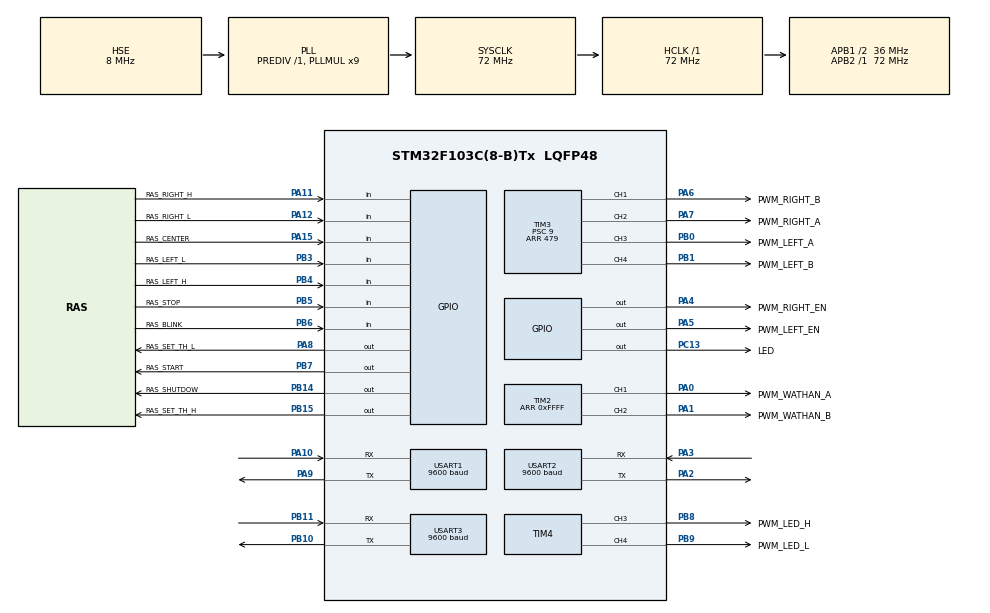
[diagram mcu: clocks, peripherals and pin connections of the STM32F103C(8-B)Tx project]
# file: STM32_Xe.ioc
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IWDG.Prescaler=IWDG_PRESCALER_64
Mcu.Family=STM32F1
Mcu.Name=STM32F103C(8-B)Tx
Mcu.Package=LQFP48
NVIC.PriorityGroup=NVIC_PRIORITYGROUP_4
NVIC.TIM1_UP_IRQn=true\:1\:0\:true\:false\:true\:true\:true
NVIC.USART1_IRQn=true\:0\:0\:false\:false\:true\:true\:true
NVIC.USART2_IRQn=true\:0\:0\:false\:false\:true\:true\:true
NVIC.USART3_IRQn=true\:0\:0\:false\:false\:true\:true\:true
PA0-WKUP.GPIO_Label=PWM_WATHAN_A
PA0-WKUP.Signal=S_TIM2_CH1_ETR
PA1.GPIO_Label=PWM_WATHAN_B
PA1.Signal=S_TIM2_CH2
PA10.GPIO_PuPd=GPIO_PULLUP
PA10.Mode=Asynchronous
PA10.Signal=USART1_RX
PA11.GPIO_Label=RAS_RIGHT_H
PA11.GPIO_PuPd=GPIO_PULLUP
PA11.Signal=GPIO_Input
PA12.GPIO_Label=RAS_RIGHT_L
PA12.GPIO_PuPd=GPIO_PULLUP
PA12.Signal=GPIO_Input
PA13.Mode=Serial_Wire
PA13.Signal=SYS_JTMS-SWDIO
PA14.Mode=Serial_Wire
PA14.Signal=SYS_JTCK-SWCLK
PA15.GPIO_Label=RAS_CENTER
PA15.GPIO_PuPd=GPIO_PULLUP
PA15.Signal=GPIO_Input
PA2.Mode=Asynchronous
PA2.Signal=USART2_TX
PA3.GPIO_PuPd=GPIO_PULLUP
PA3.Mode=Asynchronous
PA3.Signal=USART2_RX
PA4.GPIO_Label=PWM_RIGHT_EN
PA4.Signal=GPIO_Output
PA5.GPIO_Label=PWM_LEFT_EN
PA5.Signal=GPIO_Output
PA6.GPIO_Label=PWM_RIGHT_B
PA6.GPIO_Speed=GPIO_SPEED_FREQ_HIGH
PA6.Signal=S_TIM3_CH1
PA7.GPIO_Label=PWM_RIGHT_A
PA7.GPIO_Speed=GPIO_SPEED_FREQ_HIGH
PA7.Signal=S_TIM3_CH2
PA8.GPIO_Label=RAS_SET_TH_L
PA8.Signal=GPIO_Output
PA9.Mode=Asynchronous
PA9.Signal=USART1_TX
PB0.GPIO_Label=PWM_LEFT_A
PB0.GPIO_Speed=GPIO_SPEED_FREQ_HIGH
PB0.Signal=S_TIM3_CH3
PB1.GPIO_Label=PWM_LEFT_B
PB1.GPIO_Speed=GPIO_SPEED_FREQ_HIGH
PB1.Signal=S_TIM3_CH4
PB10.Mode=Asynchronous
PB10.Signal=USART3_TX
PB11.GPIO_PuPd=GPIO_PULLUP
PB11.Mode=Asynchronous
PB11.Signal=USART3_RX
PB14.GPIO_Label=RAS_SHUTDOW
PB14.Signal=GPIO_Output
PB15.GPIO_Label=RAS_SET_TH_H
PB15.Signal=GPIO_Output
PB3.GPIO_Label=RAS_LEFT_L
PB3.GPIO_PuPd=GPIO_PULLUP
PB3.Signal=GPIO_Input
PB4.GPIO_Label=RAS_LEFT_H
PB4.GPIO_PuPd=GPIO_PULLUP
PB4.Signal=GPIO_Input
PB5.GPIO_Label=RAS_STOP
PB5.GPIO_PuPd=GPIO_PULLUP
PB5.Signal=GPIO_Input
PB6.GPIO_Label=RAS_BLINK
PB6.GPIO_PuPd=GPIO_PULLUP
PB6.Signal=GPIO_Input
PB7.GPIO_Label=RAS_START
PB7.Signal=GPIO_Output
PB8.GPIO_Label=PWM_LED_H
PB8.Signal=S_TIM4_CH3
PB9.GPIO_Label=PWM_LED_L
PB9.Signal=S_TIM4_CH4
PC13-TAMPER-RTC.GPIO_Label=LED
PC13-TAMPER-RTC.GPIO_Speed=GPIO_SPEED_FREQ_HIGH
PC13-TAMPER-RTC.Signal=GPIO_Output
PD0-OSC_IN.Mode=HSE-External-Oscillator
PD0-OSC_IN.Signal=RCC_OSC_IN
PD1-OSC_OUT.Mode=HSE-External-Oscillator
PD1-OSC_OUT.Signal=RCC_OSC_OUT
ProjectManager.HeapSize=0x200
ProjectManager.StackSize=0x400
ProjectManager.TargetToolchain=MDK-ARM V5
RCC.AHBFreq_Value=72000000
RCC.APB1CLKDivider=RCC_HCLK_DIV2
RCC.APB1Freq_Value=36000000
RCC.APB1TimFreq_Value=72000000
RCC.APB2Freq_Value=72000000
RCC.APB2TimFreq_Value=72000000
RCC.HCLKFreq_Value=72000000
RCC.PLLMUL=RCC_PLL_MUL9
RCC.PLLSourceVirtual=RCC_PLLSOURCE_HSE
RCC.SYSCLKFreq_VALUE=72000000
RCC.SYSCLKSource=RCC_SYSCLKSOURCE_PLLCLK
RCC.USBFreq_Value=72000000
SH.S_TIM2_CH1_ETR.0=TIM2_CH1,PWM Generation1 CH1
SH.S_TIM2_CH2.0=TIM2_CH2,PWM Generation2 CH2
SH.S_TIM3_CH1.0=TIM3_CH1,PWM Generation1 CH1
SH.S_TIM3_CH2.0=TIM3_CH2,PWM Generation2 CH2
SH.S_TIM3_CH3.0=TIM3_CH3,PWM Generation3 CH3
SH.S_TIM3_CH4.0=TIM3_CH4,PWM Generation4 CH4
SH.S_TIM4_CH3.0=TIM4_CH3,PWM Generation3 CH3
SH.S_TIM4_CH4.0=TIM4_CH4,PWM Generation4 CH4
TIM1.AutoReloadPreload=TIM_AUTORELOAD_PRELOAD_ENABLE
TIM1.Period=59999
TIM1.Prescaler=11
TIM1.TIM_MasterOutputTrigger=TIM_TRGO_UPDATE
TIM2.AutoReloadPreload=TIM_AUTORELOAD_PRELOAD_DISABLE
TIM2.Channel-PWM\ Generation1\ CH1=TIM_CHANNEL_1
TIM2.Channel-PWM\ Generation2\ CH2=TIM_CHANNEL_2
TIM2.Period=0xFFFF
TIM3.Channel-PWM\ Generation1\ CH1=TIM_CHANNEL_1
TIM3.Channel-PWM\ Generation2\ CH2=TIM_CHANNEL_2
TIM3.Channel-PWM\ Generation3\ CH3=TIM_CHANNEL_3
TIM3.Channel-PWM\ Generation4\ CH4=TIM_CHANNEL_4
TIM3.Period=479
TIM3.Prescaler=9
TIM4.Channel-PWM\ Generation3\ CH3=TIM_CHANNEL_3
TIM4.Channel-PWM\ Generation4\ CH4=TIM_CHANNEL_4
USART1.BaudRate=9600
USART1.VirtualMode=VM_ASYNC
USART2.BaudRate=9600
USART2.VirtualMode=VM_ASYNC
USART3.BaudRate=9600
USART3.VirtualMode=VM_ASYNC
VP_IWDG_VS_IWDG.Mode=IWDG_Activate
VP_TIM1_VS_ClockSourceINT.Mode=Internal
VP_TIM2_VS_ClockSourceINT.Mode=Internal
VP_TIM3_VS_ClockSourceINT.Mode=Internal
VP_TIM4_VS_ClockSourceINT.Mode=Internal
board=custom

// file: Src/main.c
/* USER CODE BEGIN Header */
/**
  ******************************************************************************
  * @file           : main.c
  * @brief          : Main program body
  ******************************************************************************
  * @attention
  *
  * <h2><center>&copy; Copyright (c) 2020 STMicroelectronics.
  * All rights reserved.</center></h2>
  *
  * This software component is licensed by ST under BSD 3-Clause license,
  * the "License"; You may not use this file except in compliance with the
  * License. You may obtain a copy of the License at:
  *                        opensource.org/licenses/BSD-3-Clause
  *
  ******************************************************************************
  */
/* USER CODE END Header */
#include "main.h"

/* USER CODE BEGIN Includes */
#include "program.h"
#include "ram.h"
#include "const_def.h"
/* USER CODE END Includes */

/* USER CODE BEGIN PV */
/* Private variables ---------------------------------------------------------*/

/* USER CODE END PV */

void SystemClock_Config(void);
static void MX_GPIO_Init(void);
static void MX_USART1_UART_Init(void);
static void MX_USART2_UART_Init(void);
static void MX_TIM1_Init(void);
static void MX_IWDG_Init(void);
static void MX_TIM3_Init(void);
static void MX_USART3_UART_Init(void);
static void MX_TIM2_Init(void);
static void MX_TIM4_Init(void);
/* USER CODE BEGIN PFP */
/* Private function prototypes -----------------------------------------------*/

/* USER CODE END PFP */

int main(void)
{
  /* USER CODE BEGIN 1 */
	//unsigned short dmy;

  //-------------------------------
    //Read fact
  //dmy = read_fact();
	//dmy = 0;
  if(read_fact() == 0){
      init_fact();
      #if 0
      write_fact();
      #endif // 0
  }
	fact_bk = fact;
  //-------------------------------
  /* USER CODE END 1 */

  /* MCU Configuration--------------------------------------------------------*/

  /* Reset of all peripherals, Initializes the Flash interface and the Systick. */
  HAL_Init();

  /* Configure the system clock */
  SystemClock_Config();

  /* Initialize all configured peripherals */
  MX_GPIO_Init();
  MX_USART1_UART_Init();
  MX_USART2_UART_Init();
  MX_TIM1_Init();
  //MX_IWDG_Init();
  MX_TIM3_Init();
  MX_USART3_UART_Init();
  MX_TIM2_Init();
  MX_TIM4_Init();
  /* USER CODE BEGIN 2 */

  //-----------------------------------
  /* USER CODE END 2 */

  /* Infinite loop */
  while (1)
  {

    /* USER CODE BEGIN 3 */
		program();
  }
  /* USER CODE END 3 */
}

void SystemClock_Config(void)
{
  RCC_OscInitTypeDef RCC_OscInitStruct = {0};
  RCC_ClkInitTypeDef RCC_ClkInitStruct = {0};

  /** Initializes the RCC Oscillators according to the specified parameters
  * in the RCC_OscInitTypeDef structure.
  */
  RCC_OscInitStruct.OscillatorType = RCC_OSCILLATORTYPE_LSI|RCC_OSCILLATORTYPE_HSE;
  RCC_OscInitStruct.HSEState = RCC_HSE_ON;
  RCC_OscInitStruct.HSEPredivValue = RCC_HSE_PREDIV_DIV1;
  RCC_OscInitStruct.HSIState = RCC_HSI_ON;
  RCC_OscInitStruct.LSIState = RCC_LSI_ON;
  RCC_OscInitStruct.PLL.PLLState = RCC_PLL_ON;
  RCC_OscInitStruct.PLL.PLLSource = RCC_PLLSOURCE_HSE;
  RCC_OscInitStruct.PLL.PLLMUL = RCC_PLL_MUL9;
  if (HAL_RCC_OscConfig(&RCC_OscInitStruct) != HAL_OK)
  {
    Error_Handler();
  }
  /** Initializes the CPU, AHB and APB buses clocks
  */
  RCC_ClkInitStruct.ClockType = RCC_CLOCKTYPE_HCLK|RCC_CLOCKTYPE_SYSCLK
                              |RCC_CLOCKTYPE_PCLK1|RCC_CLOCKTYPE_PCLK2;
  RCC_ClkInitStruct.SYSCLKSource = RCC_SYSCLKSOURCE_PLLCLK;
  RCC_ClkInitStruct.AHBCLKDivider = RCC_SYSCLK_DIV1;
  RCC_ClkInitStruct.APB1CLKDivider = RCC_HCLK_DIV2;
  RCC_ClkInitStruct.APB2CLKDivider = RCC_HCLK_DIV1;

  if (HAL_RCC_ClockConfig(&RCC_ClkInitStruct, FLASH_LATENCY_2) != HAL_OK)
  {
    Error_Handler();
  }
}

static void MX_IWDG_Init(void)
{

  hiwdg.Instance = IWDG;
  hiwdg.Init.Prescaler = IWDG_PRESCALER_64;
  hiwdg.Init.Reload = 4095;
  if (HAL_IWDG_Init(&hiwdg) != HAL_OK)
  {
    Error_Handler();
  }

}

static void MX_TIM1_Init(void)
{

  TIM_ClockConfigTypeDef sClockSourceConfig = {0};
  TIM_MasterConfigTypeDef sMasterConfig = {0};

  htim1.Instance = TIM1;
  htim1.Init.Prescaler = 11;
  htim1.Init.CounterMode = TIM_COUNTERMODE_UP;
  htim1.Init.Period = 59999;
  htim1.Init.ClockDivision = TIM_CLOCKDIVISION_DIV1;
  htim1.Init.RepetitionCounter = 0;
  htim1.Init.AutoReloadPreload = TIM_AUTORELOAD_PRELOAD_ENABLE;
  if (HAL_TIM_Base_Init(&htim1) != HAL_OK)
  {
    Error_Handler();
  }
  sClockSourceConfig.ClockSource = TIM_CLOCKSOURCE_INTERNAL;
  if (HAL_TIM_ConfigClockSource(&htim1, &sClockSourceConfig) != HAL_OK)
  {
    Error_Handler();
  }
  sMasterConfig.MasterOutputTrigger = TIM_TRGO_UPDATE;
  sMasterConfig.MasterSlaveMode = TIM_MASTERSLAVEMODE_DISABLE;
  if (HAL_TIMEx_MasterConfigSynchronization(&htim1, &sMasterConfig) != HAL_OK)
  {
    Error_Handler();
  }

}

static void MX_TIM2_Init(void)
{

  TIM_ClockConfigTypeDef sClockSourceConfig = {0};
  TIM_MasterConfigTypeDef sMasterConfig = {0};
  TIM_OC_InitTypeDef sConfigOC = {0};

  htim2.Instance = TIM2;
  htim2.Init.Prescaler = 0;
  htim2.Init.CounterMode = TIM_COUNTERMODE_UP;
  htim2.Init.Period = 0xFFFF;
  htim2.Init.ClockDivision = TIM_CLOCKDIVISION_DIV1;
  htim2.Init.AutoReloadPreload = TIM_AUTORELOAD_PRELOAD_DISABLE;
  if (HAL_TIM_Base_Init(&htim2) != HAL_OK)
  {
    Error_Handler();
  }
  sClockSourceConfig.ClockSource = TIM_CLOCKSOURCE_INTERNAL;
  if (HAL_TIM_ConfigClockSource(&htim2, &sClockSourceConfig) != HAL_OK)
  {
    Error_Handler();
  }
  if (HAL_TIM_PWM_Init(&htim2) != HAL_OK)
  {
    Error_Handler();
  }
  sMasterConfig.MasterOutputTrigger = TIM_TRGO_RESET;
  sMasterConfig.MasterSlaveMode = TIM_MASTERSLAVEMODE_DISABLE;
  if (HAL_TIMEx_MasterConfigSynchronization(&htim2, &sMasterConfig) != HAL_OK)
  {
    Error_Handler();
  }
  sConfigOC.OCMode = TIM_OCMODE_PWM1;
  sConfigOC.Pulse = 0;
  sConfigOC.OCPolarity = TIM_OCPOLARITY_HIGH;
  sConfigOC.OCFastMode = TIM_OCFAST_DISABLE;
  if (HAL_TIM_PWM_ConfigChannel(&htim2, &sConfigOC, TIM_CHANNEL_1) != HAL_OK)
  {
    Error_Handler();
  }
  if (HAL_TIM_PWM_ConfigChannel(&htim2, &sConfigOC, TIM_CHANNEL_2) != HAL_OK)
  {
    Error_Handler();
  }
  HAL_TIM_MspPostInit(&htim2);

}

static void MX_TIM3_Init(void)
{

  TIM_ClockConfigTypeDef sClockSourceConfig = {0};
  TIM_MasterConfigTypeDef sMasterConfig = {0};
  TIM_OC_InitTypeDef sConfigOC = {0};

  htim3.Instance = TIM3;
  htim3.Init.Prescaler = 9;
  htim3.Init.CounterMode = TIM_COUNTERMODE_UP;
  htim3.Init.Period = 479;
  htim3.Init.ClockDivision = TIM_CLOCKDIVISION_DIV1;
  htim3.Init.AutoReloadPreload = TIM_AUTORELOAD_PRELOAD_DISABLE;
  if (HAL_TIM_Base_Init(&htim3) != HAL_OK)
  {
    Error_Handler();
  }
  sClockSourceConfig.ClockSource = TIM_CLOCKSOURCE_INTERNAL;
  if (HAL_TIM_ConfigClockSource(&htim3, &sClockSourceConfig) != HAL_OK)
  {
    Error_Handler();
  }
  if (HAL_TIM_PWM_Init(&htim3) != HAL_OK)
  {
    Error_Handler();
  }
  sMasterConfig.MasterOutputTrigger = TIM_TRGO_RESET;
  sMasterConfig.MasterSlaveMode = TIM_MASTERSLAVEMODE_DISABLE;
  if (HAL_TIMEx_MasterConfigSynchronization(&htim3, &sMasterConfig) != HAL_OK)
  {
    Error_Handler();
  }
  sConfigOC.OCMode = TIM_OCMODE_PWM1;
  sConfigOC.Pulse = 0;
  sConfigOC.OCPolarity = TIM_OCPOLARITY_HIGH;
  sConfigOC.OCFastMode = TIM_OCFAST_DISABLE;
  if (HAL_TIM_PWM_ConfigChannel(&htim3, &sConfigOC, TIM_CHANNEL_1) != HAL_OK)
  {
    Error_Handler();
  }
  if (HAL_TIM_PWM_ConfigChannel(&htim3, &sConfigOC, TIM_CHANNEL_2) != HAL_OK)
  {
    Error_Handler();
  }
  if (HAL_TIM_PWM_ConfigChannel(&htim3, &sConfigOC, TIM_CHANNEL_3) != HAL_OK)
  {
    Error_Handler();
  }
  if (HAL_TIM_PWM_ConfigChannel(&htim3, &sConfigOC, TIM_CHANNEL_4) != HAL_OK)
  {
    Error_Handler();
  }
  HAL_TIM_MspPostInit(&htim3);

}

static void MX_TIM4_Init(void)
{

  TIM_ClockConfigTypeDef sClockSourceConfig = {0};
  TIM_MasterConfigTypeDef sMasterConfig = {0};
  TIM_OC_InitTypeDef sConfigOC = {0};

  htim4.Instance = TIM4;
  htim4.Init.Prescaler = 0;
  htim4.Init.CounterMode = TIM_COUNTERMODE_UP;
  htim4.Init.Period = 65535;
  htim4.Init.ClockDivision = TIM_CLOCKDIVISION_DIV1;
  htim4.Init.AutoReloadPreload = TIM_AUTORELOAD_PRELOAD_DISABLE;
  if (HAL_TIM_Base_Init(&htim4) != HAL_OK)
  {
    Error_Handler();
  }
  sClockSourceConfig.ClockSource = TIM_CLOCKSOURCE_INTERNAL;
  if (HAL_TIM_ConfigClockSource(&htim4, &sClockSourceConfig) != HAL_OK)
  {
    Error_Handler();
  }
  if (HAL_TIM_PWM_Init(&htim4) != HAL_OK)
  {
    Error_Handler();
  }
  sMasterConfig.MasterOutputTrigger = TIM_TRGO_RESET;
  sMasterConfig.MasterSlaveMode = TIM_MASTERSLAVEMODE_DISABLE;
  if (HAL_TIMEx_MasterConfigSynchronization(&htim4, &sMasterConfig) != HAL_OK)
  {
    Error_Handler();
  }
  sConfigOC.OCMode = TIM_OCMODE_PWM1;
  sConfigOC.Pulse = 0;
  sConfigOC.OCPolarity = TIM_OCPOLARITY_HIGH;
  sConfigOC.OCFastMode = TIM_OCFAST_DISABLE;
  if (HAL_TIM_PWM_ConfigChannel(&htim4, &sConfigOC, TIM_CHANNEL_3) != HAL_OK)
  {
    Error_Handler();
  }
  if (HAL_TIM_PWM_ConfigChannel(&htim4, &sConfigOC, TIM_CHANNEL_4) != HAL_OK)
  {
    Error_Handler();
  }
  HAL_TIM_MspPostInit(&htim4);

}

static void MX_USART1_UART_Init(void)
{

  huart1.Instance = USART1;
  huart1.Init.BaudRate = 9600;
  huart1.Init.WordLength = UART_WORDLENGTH_8B;
  huart1.Init.StopBits = UART_STOPBITS_1;
  huart1.Init.Parity = UART_PARITY_NONE;
  huart1.Init.Mode = UART_MODE_TX_RX;
  huart1.Init.HwFlowCtl = UART_HWCONTROL_NONE;
  huart1.Init.OverSampling = UART_OVERSAMPLING_16;
  if (HAL_UART_Init(&huart1) != HAL_OK)
  {
    Error_Handler();
  }

}

static void MX_USART2_UART_Init(void)
{

  huart2.Instance = USART2;
  huart2.Init.BaudRate = 115200;
  huart2.Init.WordLength = UART_WORDLENGTH_8B;
  huart2.Init.StopBits = UART_STOPBITS_1;
  huart2.Init.Parity = UART_PARITY_NONE;
  huart2.Init.Mode = UART_MODE_TX_RX;
  huart2.Init.HwFlowCtl = UART_HWCONTROL_NONE;
  huart2.Init.OverSampling = UART_OVERSAMPLING_16;
  if (HAL_UART_Init(&huart2) != HAL_OK)
  {
    Error_Handler();
  }

}

static void MX_USART3_UART_Init(void)
{

  huart3.Instance = USART3;
  huart3.Init.BaudRate = 115200;
  huart3.Init.WordLength = UART_WORDLENGTH_8B;
  huart3.Init.StopBits = UART_STOPBITS_1;
  huart3.Init.Parity = UART_PARITY_NONE;
  huart3.Init.Mode = UART_MODE_TX_RX;
  huart3.Init.HwFlowCtl = UART_HWCONTROL_NONE;
  huart3.Init.OverSampling = UART_OVERSAMPLING_16;
  if (HAL_UART_Init(&huart3) != HAL_OK)
  {
    Error_Handler();
  }

}

static void MX_GPIO_Init(void)
{
  GPIO_InitTypeDef GPIO_InitStruct = {0};

  /* GPIO Ports Clock Enable */
  __HAL_RCC_GPIOC_CLK_ENABLE();
  __HAL_RCC_GPIOD_CLK_ENABLE();
  __HAL_RCC_GPIOA_CLK_ENABLE();
  __HAL_RCC_GPIOB_CLK_ENABLE();

  /*Configure GPIO pin Output Level */
  HAL_GPIO_WritePin(LED_GPIO_Port, LED_Pin, GPIO_PIN_RESET);

  /*Configure GPIO pin Output Level */
  HAL_GPIO_WritePin(GPIOA, PWM_RIGHT_EN_Pin|PWM_LEFT_EN_Pin|RAS_SET_TH_L_Pin, GPIO_PIN_RESET);

  /*Configure GPIO pin Output Level */
  HAL_GPIO_WritePin(GPIOB, RAS_SHUTDOW_Pin|RAS_SET_TH_H_Pin|RAS_START_Pin, GPIO_PIN_RESET);

  /*Configure GPIO pin : LED_Pin */
  GPIO_InitStruct.Pin = LED_Pin;
  GPIO_InitStruct.Mode = GPIO_MODE_OUTPUT_PP;
  GPIO_InitStruct.Pull = GPIO_NOPULL;
  GPIO_InitStruct.Speed = GPIO_SPEED_FREQ_HIGH;
  HAL_GPIO_Init(LED_GPIO_Port, &GPIO_InitStruct);

  /*Configure GPIO pins : PWM_RIGHT_EN_Pin PWM_LEFT_EN_Pin RAS_SET_TH_L_Pin */
  GPIO_InitStruct.Pin = PWM_RIGHT_EN_Pin|PWM_LEFT_EN_Pin|RAS_SET_TH_L_Pin;
  GPIO_InitStruct.Mode = GPIO_MODE_OUTPUT_PP;
  GPIO_InitStruct.Pull = GPIO_NOPULL;
  GPIO_InitStruct.Speed = GPIO_SPEED_FREQ_LOW;
  HAL_GPIO_Init(GPIOA, &GPIO_InitStruct);

  /*Configure GPIO pins : RAS_SHUTDOW_Pin RAS_SET_TH_H_Pin RAS_START_Pin */
  GPIO_InitStruct.Pin = RAS_SHUTDOW_Pin|RAS_SET_TH_H_Pin|RAS_START_Pin;
  GPIO_InitStruct.Mode = GPIO_MODE_OUTPUT_PP;
  GPIO_InitStruct.Pull = GPIO_NOPULL;
  GPIO_InitStruct.Speed = GPIO_SPEED_FREQ_LOW;
  HAL_GPIO_Init(GPIOB, &GPIO_InitStruct);

  /*Configure GPIO pins : RAS_RIGHT_H_Pin RAS_RIGHT_L_Pin RAS_CENTER_Pin */
  GPIO_InitStruct.Pin = RAS_RIGHT_H_Pin|RAS_RIGHT_L_Pin|RAS_CENTER_Pin;
  GPIO_InitStruct.Mode = GPIO_MODE_INPUT;
  GPIO_InitStruct.Pull = GPIO_PULLUP;
  HAL_GPIO_Init(GPIOA, &GPIO_InitStruct);

  /*Configure GPIO pins : RAS_LEFT_L_Pin RAS_LEFT_H_Pin RAS_STOP_Pin RAS_BLINK_Pin */
  GPIO_InitStruct.Pin = RAS_LEFT_L_Pin|RAS_LEFT_H_Pin|RAS_STOP_Pin|RAS_BLINK_Pin;
  GPIO_InitStruct.Mode = GPIO_MODE_INPUT;
  GPIO_InitStruct.Pull = GPIO_PULLUP;
  HAL_GPIO_Init(GPIOB, &GPIO_InitStruct);

}

void Error_Handler(void)
{
  while(1)
  {
  }
}

/************************ (C) COPYRIGHT STMicroelectronics *****END OF FILE****/
